AUTOSAR XML (schema 4-3-0)
package /Comp_FDC_ARPkg
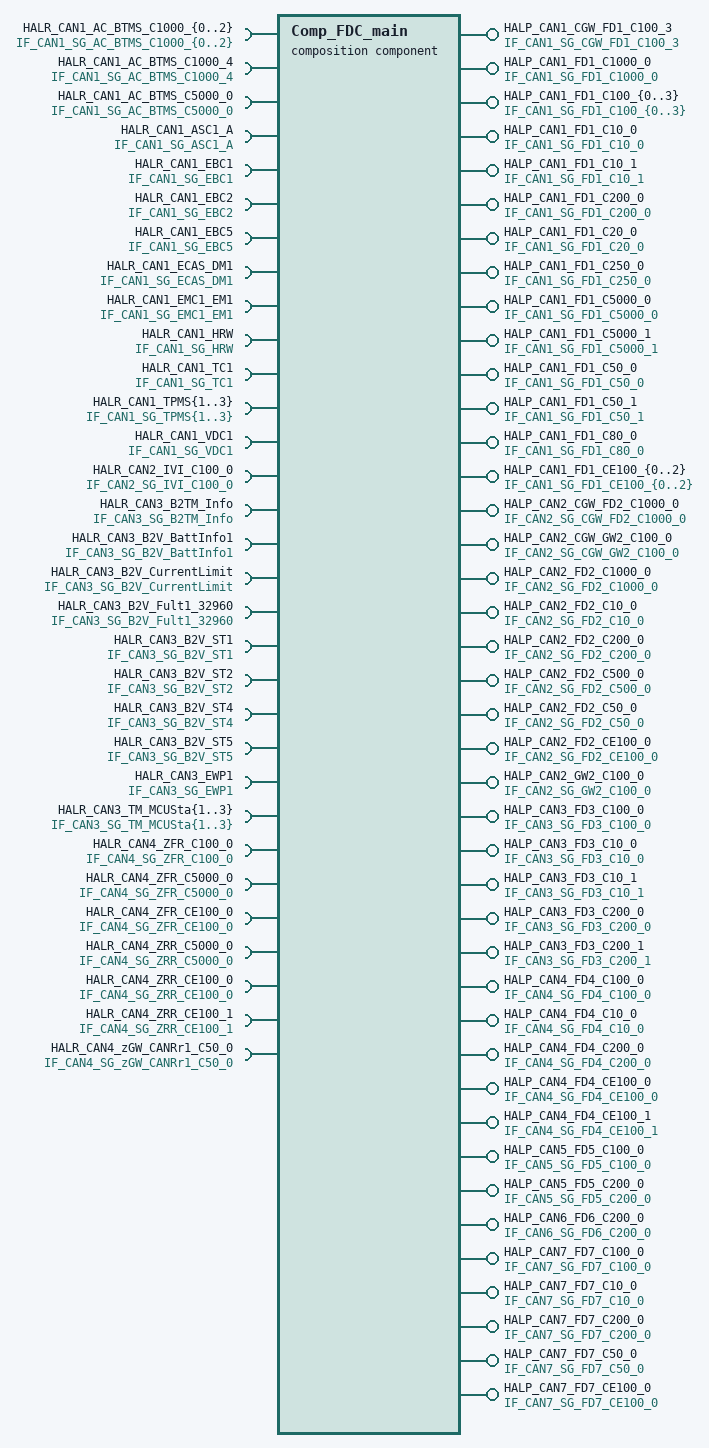
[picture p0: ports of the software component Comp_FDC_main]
  composition sw component type Comp_FDC_main
    46 x provide port:
      HALP_CAN1_CGW_FD1_C100_3: nonqueued-sender-com-spec{data-element=CAN1_SG_CGW_FD1_C100_3, handle-out-of-range=DEFAULT, init-value=constant-reference=Init_CAN1_SG_CGW_FD1_C100_3}, provided-interface=IF_CAN1_SG_CGW_FD1_C100_3
      HALP_CAN1_FD1_C1000_0: nonqueued-sender-com-spec{data-element=CAN1_SG_FD1_C1000_0, handle-out-of-range=DEFAULT, init-value=constant-reference=Init_CAN1_SG_FD1_C1000_0}, provided-interface=IF_CAN1_SG_FD1_C1000_0
      HALP_CAN1_FD1_C100_{0..3}: nonqueued-sender-com-spec{data-element=CAN1_SG_FD1_C100_{0..3}, handle-out-of-range=DEFAULT, init-value=constant-reference=Init_CAN1_SG_FD1_C100_{0..3}}, provided-interface=IF_CAN1_SG_FD1_C100_{0..3}
      HALP_CAN1_FD1_C10_0: nonqueued-sender-com-spec{data-element=CAN1_SG_FD1_C10_0, handle-out-of-range=DEFAULT, init-value=constant-reference=Init_CAN1_SG_FD1_C10_0}, provided-interface=IF_CAN1_SG_FD1_C10_0
      HALP_CAN1_FD1_C10_1: nonqueued-sender-com-spec{data-element=CAN1_SG_FD1_C10_1, handle-out-of-range=DEFAULT, init-value=constant-reference=Init_CAN1_SG_FD1_C10_1}, provided-interface=IF_CAN1_SG_FD1_C10_1
      HALP_CAN1_FD1_C200_0: nonqueued-sender-com-spec{data-element=CAN1_SG_FD1_C200_0, handle-out-of-range=DEFAULT, init-value=constant-reference=Init_CAN1_SG_FD1_C200_0}, provided-interface=IF_CAN1_SG_FD1_C200_0
      HALP_CAN1_FD1_C20_0: nonqueued-sender-com-spec{data-element=CAN1_SG_FD1_C20_0, handle-out-of-range=DEFAULT, init-value=constant-reference=Init_CAN1_SG_FD1_C20_0}, provided-interface=IF_CAN1_SG_FD1_C20_0
      HALP_CAN1_FD1_C250_0: nonqueued-sender-com-spec{data-element=CAN1_SG_FD1_C250_0, handle-out-of-range=DEFAULT, init-value=constant-reference=Init_CAN1_SG_FD1_C250_0}, provided-interface=IF_CAN1_SG_FD1_C250_0
      HALP_CAN1_FD1_C5000_0: nonqueued-sender-com-spec{data-element=CAN1_SG_FD1_C5000_0, handle-out-of-range=DEFAULT, init-value=constant-reference=Init_CAN1_SG_FD1_C5000_0}, provided-interface=IF_CAN1_SG_FD1_C5000_0
      HALP_CAN1_FD1_C5000_1: nonqueued-sender-com-spec{data-element=CAN1_SG_FD1_C5000_1, handle-out-of-range=DEFAULT, init-value=constant-reference=Init_CAN1_SG_FD1_C5000_1}, provided-interface=IF_CAN1_SG_FD1_C5000_1
      HALP_CAN1_FD1_C50_0: nonqueued-sender-com-spec{data-element=CAN1_SG_FD1_C50_0, handle-out-of-range=DEFAULT, init-value=constant-reference=Init_CAN1_SG_FD1_C50_0}, provided-interface=IF_CAN1_SG_FD1_C50_0
      HALP_CAN1_FD1_C50_1: nonqueued-sender-com-spec{data-element=CAN1_SG_FD1_C50_1, handle-out-of-range=DEFAULT, init-value=constant-reference=Init_CAN1_SG_FD1_C50_1}, provided-interface=IF_CAN1_SG_FD1_C50_1
      HALP_CAN1_FD1_C80_0: nonqueued-sender-com-spec{data-element=CAN1_SG_FD1_C80_0, handle-out-of-range=DEFAULT, init-value=constant-reference=Init_CAN1_SG_FD1_C80_0}, provided-interface=IF_CAN1_SG_FD1_C80_0
      HALP_CAN1_FD1_CE100_{0..2}: nonqueued-sender-com-spec{data-element=CAN1_SG_FD1_CE100_{0..2}, handle-out-of-range=DEFAULT, init-value=constant-reference=Init_CAN1_SG_FD1_CE100_{0..2}}, provided-interface=IF_CAN1_SG_FD1_CE100_{0..2}
      HALP_CAN2_CGW_FD2_C1000_0: nonqueued-sender-com-spec{data-element=CAN2_SG_CGW_FD2_C1000_0, handle-out-of-range=DEFAULT, init-value=constant-reference=Init_CAN2_SG_CGW_FD2_C1000_0}, provided-interface=IF_CAN2_SG_CGW_FD2_C1000_0
      HALP_CAN2_CGW_GW2_C100_0: nonqueued-sender-com-spec{data-element=CAN2_SG_CGW_GW2_C100_0, handle-out-of-range=DEFAULT, init-value=constant-reference=Init_CAN2_SG_CGW_GW2_C100_0}, provided-interface=IF_CAN2_SG_CGW_GW2_C100_0
      HALP_CAN2_FD2_C1000_0: nonqueued-sender-com-spec{data-element=CAN2_SG_FD2_C1000_0, handle-out-of-range=DEFAULT, init-value=constant-reference=Init_CAN2_SG_FD2_C1000_0}, provided-interface=IF_CAN2_SG_FD2_C1000_0
      HALP_CAN2_FD2_C10_0: nonqueued-sender-com-spec{data-element=CAN2_SG_FD2_C10_0, handle-out-of-range=DEFAULT, init-value=constant-reference=Init_CAN2_SG_FD2_C10_0}, provided-interface=IF_CAN2_SG_FD2_C10_0
      HALP_CAN2_FD2_C200_0: nonqueued-sender-com-spec{data-element=CAN2_SG_FD2_C200_0, handle-out-of-range=DEFAULT, init-value=constant-reference=Init_CAN2_SG_FD2_C200_0}, provided-interface=IF_CAN2_SG_FD2_C200_0
      HALP_CAN2_FD2_C500_0: nonqueued-sender-com-spec{data-element=CAN2_SG_FD2_C500_0, handle-out-of-range=DEFAULT, init-value=constant-reference=Init_CAN2_SG_FD2_C500_0}, provided-interface=IF_CAN2_SG_FD2_C500_0
      HALP_CAN2_FD2_C50_0: nonqueued-sender-com-spec{data-element=CAN2_SG_FD2_C50_0, handle-out-of-range=DEFAULT, init-value=constant-reference=Init_CAN2_SG_FD2_C50_0}, provided-interface=IF_CAN2_SG_FD2_C50_0
      HALP_CAN2_FD2_CE100_0: nonqueued-sender-com-spec{data-element=CAN2_SG_FD2_CE100_0, handle-out-of-range=DEFAULT, init-value=constant-reference=Init_CAN2_SG_FD2_CE100_0}, provided-interface=IF_CAN2_SG_FD2_CE100_0
      HALP_CAN2_GW2_C100_0: nonqueued-sender-com-spec{data-element=CAN2_SG_GW2_C100_0, handle-out-of-range=DEFAULT, init-value=constant-reference=Init_CAN2_SG_GW2_C100_0}, provided-interface=IF_CAN2_SG_GW2_C100_0
      HALP_CAN3_FD3_C100_0: nonqueued-sender-com-spec{data-element=CAN3_SG_FD3_C100_0, handle-out-of-range=DEFAULT, init-value=constant-reference=Init_CAN3_SG_FD3_C100_0}, provided-interface=IF_CAN3_SG_FD3_C100_0
      HALP_CAN3_FD3_C10_0: nonqueued-sender-com-spec{data-element=CAN3_SG_FD3_C10_0, handle-out-of-range=DEFAULT, init-value=constant-reference=Init_CAN3_SG_FD3_C10_0}, provided-interface=IF_CAN3_SG_FD3_C10_0
      HALP_CAN3_FD3_C10_1: nonqueued-sender-com-spec{data-element=CAN3_SG_FD3_C10_1, handle-out-of-range=DEFAULT, init-value=constant-reference=Init_CAN3_SG_FD3_C10_1}, provided-interface=IF_CAN3_SG_FD3_C10_1
      HALP_CAN3_FD3_C200_0: nonqueued-sender-com-spec{data-element=CAN3_SG_FD3_C200_0, handle-out-of-range=DEFAULT, init-value=constant-reference=Init_CAN3_SG_FD3_C200_0}, provided-interface=IF_CAN3_SG_FD3_C200_0
      HALP_CAN3_FD3_C200_1: nonqueued-sender-com-spec{data-element=CAN3_SG_FD3_C200_1, handle-out-of-range=DEFAULT, init-value=constant-reference=Init_CAN3_SG_FD3_C200_1}, provided-interface=IF_CAN3_SG_FD3_C200_1
      HALP_CAN4_FD4_C100_0: nonqueued-sender-com-spec{data-element=CAN4_SG_FD4_C100_0, handle-out-of-range=DEFAULT, init-value=constant-reference=Init_CAN4_SG_FD4_C100_0}, provided-interface=IF_CAN4_SG_FD4_C100_0
      HALP_CAN4_FD4_C10_0: nonqueued-sender-com-spec{data-element=CAN4_SG_FD4_C10_0, handle-out-of-range=DEFAULT, init-value=constant-reference=Init_CAN4_SG_FD4_C10_0}, provided-interface=IF_CAN4_SG_FD4_C10_0
      HALP_CAN4_FD4_C200_0: nonqueued-sender-com-spec{data-element=CAN4_SG_FD4_C200_0, handle-out-of-range=DEFAULT, init-value=constant-reference=Init_CAN4_SG_FD4_C200_0}, provided-interface=IF_CAN4_SG_FD4_C200_0
      HALP_CAN4_FD4_CE100_0: nonqueued-sender-com-spec{data-element=CAN4_SG_FD4_CE100_0, handle-out-of-range=DEFAULT, init-value=constant-reference=Init_CAN4_SG_FD4_CE100_0}, provided-interface=IF_CAN4_SG_FD4_CE100_0
      HALP_CAN4_FD4_CE100_1: nonqueued-sender-com-spec{data-element=CAN4_SG_FD4_CE100_1, handle-out-of-range=DEFAULT, init-value=constant-reference=Init_CAN4_SG_FD4_CE100_1}, provided-interface=IF_CAN4_SG_FD4_CE100_1
      HALP_CAN5_FD5_C100_0: nonqueued-sender-com-spec{data-element=CAN5_SG_FD5_C100_0, handle-out-of-range=DEFAULT, init-value=constant-reference=Init_CAN5_SG_FD5_C100_0}, provided-interface=IF_CAN5_SG_FD5_C100_0
      HALP_CAN5_FD5_C200_0: nonqueued-sender-com-spec{data-element=CAN5_SG_FD5_C200_0, handle-out-of-range=DEFAULT, init-value=constant-reference=Init_CAN5_SG_FD5_C200_0}, provided-interface=IF_CAN5_SG_FD5_C200_0
      HALP_CAN6_FD6_C200_0: nonqueued-sender-com-spec{data-element=CAN6_SG_FD6_C200_0, handle-out-of-range=DEFAULT, init-value=constant-reference=Init_CAN6_SG_FD6_C200_0}, provided-interface=IF_CAN6_SG_FD6_C200_0
      HALP_CAN7_FD7_C100_0: nonqueued-sender-com-spec{data-element=CAN7_SG_FD7_C100_0, handle-out-of-range=DEFAULT, init-value=constant-reference=Init_CAN7_SG_FD7_C100_0}, provided-interface=IF_CAN7_SG_FD7_C100_0
      HALP_CAN7_FD7_C10_0: nonqueued-sender-com-spec{data-element=CAN7_SG_FD7_C10_0, handle-out-of-range=DEFAULT, init-value=constant-reference=Init_CAN7_SG_FD7_C10_0}, provided-interface=IF_CAN7_SG_FD7_C10_0
      HALP_CAN7_FD7_C200_0: nonqueued-sender-com-spec{data-element=CAN7_SG_FD7_C200_0, handle-out-of-range=DEFAULT, init-value=constant-reference=Init_CAN7_SG_FD7_C200_0}, provided-interface=IF_CAN7_SG_FD7_C200_0
      HALP_CAN7_FD7_C50_0: nonqueued-sender-com-spec{data-element=CAN7_SG_FD7_C50_0, handle-out-of-range=DEFAULT, init-value=constant-reference=Init_CAN7_SG_FD7_C50_0}, provided-interface=IF_CAN7_SG_FD7_C50_0
      HALP_CAN7_FD7_CE100_0: nonqueued-sender-com-spec{data-element=CAN7_SG_FD7_CE100_0, handle-out-of-range=DEFAULT, init-value=constant-reference=Init_CAN7_SG_FD7_CE100_0}, provided-interface=IF_CAN7_SG_FD7_CE100_0
    37 x require port:
      HALR_CAN1_AC_BTMS_C1000_{0..2}: nonqueued-receiver-com-spec{data-element=CAN1_SG_AC_BTMS_C1000_{0..2}, handle-out-of-range=DEFAULT, enable-update=true, init-value=constant-reference=Init_CAN1_SG_AC_BTMS_C1000_{0..2}}, required-interface=IF_CAN1_SG_AC_BTMS_C1000_{0..2}
      HALR_CAN1_AC_BTMS_C1000_4: nonqueued-receiver-com-spec{data-element=CAN1_SG_AC_BTMS_C1000_4, handle-out-of-range=DEFAULT, enable-update=true, init-value=constant-reference=Init_CAN1_SG_AC_BTMS_C1000_4}, required-interface=IF_CAN1_SG_AC_BTMS_C1000_4
      HALR_CAN1_AC_BTMS_C5000_0: nonqueued-receiver-com-spec{data-element=CAN1_SG_AC_BTMS_C5000_0, handle-out-of-range=DEFAULT, enable-update=true, init-value=constant-reference=Init_CAN1_SG_AC_BTMS_C5000_0}, required-interface=IF_CAN1_SG_AC_BTMS_C5000_0
      HALR_CAN1_ASC1_A: nonqueued-receiver-com-spec{data-element=CAN1_SG_ASC1_A, handle-out-of-range=DEFAULT, enable-update=true, init-value=constant-reference=Init_CAN1_SG_ASC1_A}, required-interface=IF_CAN1_SG_ASC1_A
      HALR_CAN1_EBC1: nonqueued-receiver-com-spec{data-element=CAN1_SG_EBC1, handle-out-of-range=DEFAULT, enable-update=true, init-value=constant-reference=Init_CAN1_SG_EBC1}, required-interface=IF_CAN1_SG_EBC1
      HALR_CAN1_EBC2: nonqueued-receiver-com-spec{data-element=CAN1_SG_EBC2, handle-out-of-range=DEFAULT, enable-update=true, init-value=constant-reference=Init_CAN1_SG_EBC2}, required-interface=IF_CAN1_SG_EBC2
      HALR_CAN1_EBC5: nonqueued-receiver-com-spec{data-element=CAN1_SG_EBC5, handle-out-of-range=DEFAULT, enable-update=true, init-value=constant-reference=Init_CAN1_SG_EBC5}, required-interface=IF_CAN1_SG_EBC5
      HALR_CAN1_ECAS_DM1: nonqueued-receiver-com-spec{data-element=CAN1_SG_ECAS_DM1, handle-out-of-range=DEFAULT, enable-update=true, init-value=constant-reference=Init_CAN1_SG_ECAS_DM1}, required-interface=IF_CAN1_SG_ECAS_DM1
      HALR_CAN1_EMC1_EM1: nonqueued-receiver-com-spec{data-element=CAN1_SG_EMC1_EM1, handle-out-of-range=DEFAULT, enable-update=true, init-value=constant-reference=Init_CAN1_SG_EMC1_EM1}, required-interface=IF_CAN1_SG_EMC1_EM1
      HALR_CAN1_HRW: nonqueued-receiver-com-spec{data-element=CAN1_SG_HRW, handle-out-of-range=DEFAULT, enable-update=true, init-value=constant-reference=Init_CAN1_SG_HRW}, required-interface=IF_CAN1_SG_HRW
      HALR_CAN1_TC1: nonqueued-receiver-com-spec{data-element=CAN1_SG_TC1, handle-out-of-range=DEFAULT, enable-update=true, init-value=constant-reference=Init_CAN1_SG_TC1}, required-interface=IF_CAN1_SG_TC1
      HALR_CAN1_TPMS{1..3}: nonqueued-receiver-com-spec{data-element=CAN1_SG_TPMS{1..3}, handle-out-of-range=DEFAULT, enable-update=true, init-value=constant-reference=Init_CAN1_SG_TPMS{1..3}}, required-interface=IF_CAN1_SG_TPMS{1..3}
      HALR_CAN1_VDC1: nonqueued-receiver-com-spec{data-element=CAN1_SG_VDC1, handle-out-of-range=DEFAULT, enable-update=true, init-value=constant-reference=Init_CAN1_SG_VDC1}, required-interface=IF_CAN1_SG_VDC1
      HALR_CAN2_IVI_C100_0: nonqueued-receiver-com-spec{data-element=CAN2_SG_IVI_C100_0, handle-out-of-range=DEFAULT, enable-update=true, init-value=constant-reference=Init_CAN2_SG_IVI_C100_0}, required-interface=IF_CAN2_SG_IVI_C100_0
      HALR_CAN3_B2TM_Info: nonqueued-receiver-com-spec{data-element=CAN3_SG_B2TM_Info, handle-out-of-range=DEFAULT, enable-update=true, init-value=constant-reference=Init_CAN3_SG_B2TM_Info}, required-interface=IF_CAN3_SG_B2TM_Info
      HALR_CAN3_B2V_BattInfo1: nonqueued-receiver-com-spec{data-element=CAN3_SG_B2V_BattInfo1, handle-out-of-range=DEFAULT, enable-update=true, init-value=constant-reference=Init_CAN3_SG_B2V_BattInfo1}, required-interface=IF_CAN3_SG_B2V_BattInfo1
      HALR_CAN3_B2V_CurrentLimit: nonqueued-receiver-com-spec{data-element=CAN3_SG_B2V_CurrentLimit, handle-out-of-range=DEFAULT, enable-update=true, init-value=constant-reference=Init_CAN3_SG_B2V_CurrentLimit}, required-interface=IF_CAN3_SG_B2V_CurrentLimit
      HALR_CAN3_B2V_Fult1_32960: nonqueued-receiver-com-spec{data-element=CAN3_SG_B2V_Fult1_32960, handle-out-of-range=DEFAULT, enable-update=true, init-value=constant-reference=Init_CAN3_SG_B2V_Fult1_32960}, required-interface=IF_CAN3_SG_B2V_Fult1_32960
      HALR_CAN3_B2V_ST1: nonqueued-receiver-com-spec{data-element=CAN3_SG_B2V_ST1, handle-out-of-range=DEFAULT, enable-update=true, init-value=constant-reference=Init_CAN3_SG_B2V_ST1}, required-interface=IF_CAN3_SG_B2V_ST1
      HALR_CAN3_B2V_ST2: nonqueued-receiver-com-spec{data-element=CAN3_SG_B2V_ST2, handle-out-of-range=DEFAULT, enable-update=true, init-value=constant-reference=Init_CAN3_SG_B2V_ST2}, required-interface=IF_CAN3_SG_B2V_ST2
      HALR_CAN3_B2V_ST4: nonqueued-receiver-com-spec{data-element=CAN3_SG_B2V_ST4, handle-out-of-range=DEFAULT, enable-update=true, init-value=constant-reference=Init_CAN3_SG_B2V_ST4}, required-interface=IF_CAN3_SG_B2V_ST4
      HALR_CAN3_B2V_ST5: nonqueued-receiver-com-spec{data-element=CAN3_SG_B2V_ST5, handle-out-of-range=DEFAULT, enable-update=true, init-value=constant-reference=Init_CAN3_SG_B2V_ST5}, required-interface=IF_CAN3_SG_B2V_ST5
      HALR_CAN3_EWP1: nonqueued-receiver-com-spec{data-element=CAN3_SG_EWP1, handle-out-of-range=DEFAULT, enable-update=true, init-value=constant-reference=Init_CAN3_SG_EWP1}, required-interface=IF_CAN3_SG_EWP1
      HALR_CAN3_TM_MCUSta{1..3}: nonqueued-receiver-com-spec{data-element=CAN3_SG_TM_MCUSta{1..3}, handle-out-of-range=DEFAULT, enable-update=true, init-value=constant-reference=Init_CAN3_SG_TM_MCUSta{1..3}}, required-interface=IF_CAN3_SG_TM_MCUSta{1..3}
      HALR_CAN4_ZFR_C100_0: nonqueued-receiver-com-spec{data-element=CAN4_SG_ZFR_C100_0, handle-out-of-range=DEFAULT, enable-update=true, init-value=constant-reference=Init_CAN4_SG_ZFR_C100_0}, required-interface=IF_CAN4_SG_ZFR_C100_0
      HALR_CAN4_ZFR_C5000_0: nonqueued-receiver-com-spec{data-element=CAN4_SG_ZFR_C5000_0, handle-out-of-range=DEFAULT, enable-update=true, init-value=constant-reference=Init_CAN4_SG_ZFR_C5000_0}, required-interface=IF_CAN4_SG_ZFR_C5000_0
      HALR_CAN4_ZFR_CE100_0: nonqueued-receiver-com-spec{data-element=CAN4_SG_ZFR_CE100_0, handle-out-of-range=DEFAULT, enable-update=true, init-value=constant-reference=Init_CAN4_SG_ZFR_CE100_0}, required-interface=IF_CAN4_SG_ZFR_CE100_0
      HALR_CAN4_ZRR_C5000_0: nonqueued-receiver-com-spec{data-element=CAN4_SG_ZRR_C5000_0, handle-out-of-range=DEFAULT, enable-update=true, init-value=constant-reference=Init_CAN4_SG_ZRR_C5000_0}, required-interface=IF_CAN4_SG_ZRR_C5000_0
      HALR_CAN4_ZRR_CE100_0: nonqueued-receiver-com-spec{data-element=CAN4_SG_ZRR_CE100_0, handle-out-of-range=DEFAULT, enable-update=true, init-value=constant-reference=Init_CAN4_SG_ZRR_CE100_0}, required-interface=IF_CAN4_SG_ZRR_CE100_0
      HALR_CAN4_ZRR_CE100_1: nonqueued-receiver-com-spec{data-element=CAN4_SG_ZRR_CE100_1, handle-out-of-range=DEFAULT, enable-update=true, init-value=constant-reference=Init_CAN4_SG_ZRR_CE100_1}, required-interface=IF_CAN4_SG_ZRR_CE100_1
      HALR_CAN4_zGW_CANRr1_C50_0: nonqueued-receiver-com-spec{data-element=CAN4_SG_zGW_CANRr1_C50_0, handle-out-of-range=DEFAULT, enable-update=true, init-value=constant-reference=Init_CAN4_SG_zGW_CANRr1_C50_0}, required-interface=IF_CAN4_SG_zGW_CANRr1_C50_0
    20 x component:
      BswMTest: type=BswMTest_type
      SWC_APS: type=SWC_APS_type
      SWC_CDD: type=SWC_CDD_type
      SWC_CGW: type=SWC_CGW_type
      SWC_DID: type=SWC_DID_type
      SWC_DKC: type=SWC_DKC_type
      SWC_FDC: type=SWC_FDC_type
      SWC_HALIN: type=SWC_HALIN_type
      SWC_HALIN_CDD: type=SWC_HALIN_CDD_type
      SWC_IMU: type=SWC_IMU_type
      SWC_INP: type=SWC_INP_type
      SWC_IOEXP: type=SWC_IOEXP_type
      SWC_OUTP: type=SWC_OUTP_type
      SWC_HALOUT: type=SWC_HALOUT_type
      SWC_LOG: type=SWC_LOG_type
      SWC_NVM: type=SWC_NVM_type
      SWC_SCP: type=SWC_SCP_type
      SWC_UART: type=SWC_UART_type
      SWC_UDS: type=SWC_UDS_type
      SWC_VES: type=SWC_VES_type
    delegate SWC_HALIN.R_CAN1_AC_BTMS_C1000_0 <-> outer port HALR_CAN1_AC_BTMS_C1000_0
    delegate SWC_HALIN.R_CAN1_AC_BTMS_C1000_1 <-> outer port HALR_CAN1_AC_BTMS_C1000_1
    delegate SWC_HALIN.R_CAN1_AC_BTMS_C1000_4 <-> outer port HALR_CAN1_AC_BTMS_C1000_4
    delegate SWC_HALIN.R_CAN1_AC_BTMS_C5000_0 <-> outer port HALR_CAN1_AC_BTMS_C5000_0
    delegate SWC_HALIN.R_CAN1_ASC1_A <-> outer port HALR_CAN1_ASC1_A
    delegate SWC_HALIN.R_CAN1_EBC1 <-> outer port HALR_CAN1_EBC1
    delegate SWC_HALIN.R_CAN1_EBC2 <-> outer port HALR_CAN1_EBC2
    delegate SWC_HALIN.R_CAN1_EBC5 <-> outer port HALR_CAN1_EBC5
    delegate SWC_HALIN.R_CAN1_ECAS_DM1 <-> outer port HALR_CAN1_ECAS_DM1
    delegate SWC_HALIN.R_CAN1_EMC1_EM1 <-> outer port HALR_CAN1_EMC1_EM1
    delegate SWC_HALIN.R_CAN1_HRW <-> outer port HALR_CAN1_HRW
    delegate SWC_HALIN.R_CAN1_TC1 <-> outer port HALR_CAN1_TC1
    delegate SWC_HALIN.R_CAN2_IVI_C100_0 <-> outer port HALR_CAN2_IVI_C100_0
    delegate SWC_HALIN.R_CAN3_B2TM_Info <-> outer port HALR_CAN3_B2TM_Info
    delegate SWC_HALIN.R_CAN3_B2V_BattInfo1 <-> outer port HALR_CAN3_B2V_BattInfo1
    delegate SWC_HALIN.R_CAN3_B2V_CurrentLimit <-> outer port HALR_CAN3_B2V_CurrentLimit
    delegate SWC_HALIN.R_CAN3_B2V_Fult1_32960 <-> outer port HALR_CAN3_B2V_Fult1_32960
    delegate SWC_HALIN.R_CAN3_B2V_ST1 <-> outer port HALR_CAN3_B2V_ST1
    delegate SWC_HALIN.R_CAN3_B2V_ST2 <-> outer port HALR_CAN3_B2V_ST2
    delegate SWC_HALIN.R_CAN3_B2V_ST4 <-> outer port HALR_CAN3_B2V_ST4
    delegate SWC_HALIN.R_CAN3_B2V_ST5 <-> outer port HALR_CAN3_B2V_ST5
    delegate SWC_HALIN.R_CAN3_EWP1 <-> outer port HALR_CAN3_EWP1
    delegate SWC_HALIN.R_CAN3_TM_MCUSta{1..3} <-> outer port HALR_CAN3_TM_MCUSta{1..3}
    delegate SWC_HALIN.R_CAN4_ZFR_C100_0 <-> outer port HALR_CAN4_ZFR_C100_0
    delegate SWC_HALIN.R_CAN4_ZFR_CE100_0 <-> outer port HALR_CAN4_ZFR_CE100_0
    delegate SWC_HALIN.R_CAN4_ZRR_CE100_0 <-> outer port HALR_CAN4_ZRR_CE100_0
    delegate SWC_HALIN.R_CAN4_ZRR_CE100_1 <-> outer port HALR_CAN4_ZRR_CE100_1
    delegate SWC_HALIN.R_CAN4_zGW_CANRr1_C50_0 <-> outer port HALR_CAN4_zGW_CANRr1_C50_0
    delegate SWC_CGW.R_CAN1_AC_BTMS_C1000_1 <-> outer port HALR_CAN1_AC_BTMS_C1000_1
    delegate SWC_CGW.R_CAN1_AC_BTMS_C1000_2 <-> outer port HALR_CAN1_AC_BTMS_C1000_2
    delegate SWC_CGW.R_CAN1_AC_BTMS_C5000_0 <-> outer port HALR_CAN1_AC_BTMS_C5000_0
    delegate SWC_CGW.R_CAN1_ASC1_A <-> outer port HALR_CAN1_ASC1_A
    delegate SWC_CGW.R_CAN1_EBC1 <-> outer port HALR_CAN1_EBC1
    delegate SWC_CGW.R_CAN1_ECAS_DM1 <-> outer port HALR_CAN1_ECAS_DM1
    delegate SWC_CGW.R_CAN1_HRW <-> outer port HALR_CAN1_HRW
    delegate SWC_CGW.R_CAN1_TC1 <-> outer port HALR_CAN1_TC1
    delegate SWC_CGW.R_CAN1_TPMS{1..3} <-> outer port HALR_CAN1_TPMS{1..3}
    delegate SWC_CGW.R_CAN1_VDC1 <-> outer port HALR_CAN1_VDC1
    delegate SWC_CGW.R_CAN3_B2TM_Info <-> outer port HALR_CAN3_B2TM_Info
    delegate SWC_CGW.R_CAN3_B2V_BattInfo1 <-> outer port HALR_CAN3_B2V_BattInfo1
    delegate SWC_CGW.R_CAN3_B2V_ST1 <-> outer port HALR_CAN3_B2V_ST1
    delegate SWC_CGW.R_CAN3_B2V_ST2 <-> outer port HALR_CAN3_B2V_ST2
    delegate SWC_CGW.R_CAN3_TM_MCUSta2 <-> outer port HALR_CAN3_TM_MCUSta2
    delegate SWC_CGW.R_CAN4_ZFR_C100_0 <-> outer port HALR_CAN4_ZFR_C100_0
    delegate SWC_CGW.R_CAN4_ZFR_C5000_0 <-> outer port HALR_CAN4_ZFR_C5000_0
    delegate SWC_CGW.R_CAN4_ZFR_CE100_0 <-> outer port HALR_CAN4_ZFR_CE100_0
    delegate SWC_CGW.R_CAN4_ZRR_C5000_0 <-> outer port HALR_CAN4_ZRR_C5000_0
    delegate SWC_CGW.R_CAN4_ZRR_CE100_1 <-> outer port HALR_CAN4_ZRR_CE100_1
    delegate SWC_CGW.R_CAN4_zGW_CANRr1_C50_0 <-> outer port HALR_CAN4_zGW_CANRr1_C50_0
    delegate SWC_HALOUT.P_CAN1_FD1_C100_{0..3} <-> outer port HALP_CAN1_FD1_C100_{0..3}
    delegate SWC_HALOUT.P_CAN1_FD1_C10_0 <-> outer port HALP_CAN1_FD1_C10_0
    delegate SWC_HALOUT.P_CAN1_FD1_C10_1 <-> outer port HALP_CAN1_FD1_C10_1
    delegate SWC_HALOUT.P_CAN1_FD1_C200_0 <-> outer port HALP_CAN1_FD1_C200_0
    delegate SWC_HALOUT.P_CAN1_FD1_C20_0 <-> outer port HALP_CAN1_FD1_C20_0
    delegate SWC_HALOUT.P_CAN1_FD1_C250_0 <-> outer port HALP_CAN1_FD1_C250_0
    delegate SWC_HALOUT.P_CAN1_FD1_C5000_0 <-> outer port HALP_CAN1_FD1_C5000_0
    delegate SWC_HALOUT.P_CAN1_FD1_C5000_1 <-> outer port HALP_CAN1_FD1_C5000_1
    delegate SWC_HALOUT.P_CAN1_FD1_C50_0 <-> outer port HALP_CAN1_FD1_C50_0
    delegate SWC_HALOUT.P_CAN1_FD1_C50_1 <-> outer port HALP_CAN1_FD1_C50_1
    delegate SWC_HALOUT.P_CAN1_FD1_C80_0 <-> outer port HALP_CAN1_FD1_C80_0
    delegate SWC_HALOUT.P_CAN1_FD1_CE100_{0..2} <-> outer port HALP_CAN1_FD1_CE100_{0..2}
    delegate SWC_HALOUT.P_CAN2_FD2_C1000_0 <-> outer port HALP_CAN2_FD2_C1000_0
    delegate SWC_HALOUT.P_CAN2_FD2_C10_0 <-> outer port HALP_CAN2_FD2_C10_0
    delegate SWC_HALOUT.P_CAN2_FD2_C200_0 <-> outer port HALP_CAN2_FD2_C200_0
    delegate SWC_HALOUT.P_CAN2_FD2_C500_0 <-> outer port HALP_CAN2_FD2_C500_0
    delegate SWC_HALOUT.P_CAN2_FD2_C50_0 <-> outer port HALP_CAN2_FD2_C50_0
    delegate SWC_HALOUT.P_CAN2_FD2_CE100_0 <-> outer port HALP_CAN2_FD2_CE100_0
    delegate SWC_HALOUT.P_CAN2_GW2_C100_0 <-> outer port HALP_CAN2_GW2_C100_0
    delegate SWC_HALOUT.P_CAN3_FD3_C100_0 <-> outer port HALP_CAN3_FD3_C100_0
    delegate SWC_HALOUT.P_CAN3_FD3_C10_0 <-> outer port HALP_CAN3_FD3_C10_0
    delegate SWC_HALOUT.P_CAN3_FD3_C10_1 <-> outer port HALP_CAN3_FD3_C10_1
    delegate SWC_HALOUT.P_CAN3_FD3_C200_0 <-> outer port HALP_CAN3_FD3_C200_0
    delegate SWC_HALOUT.P_CAN3_FD3_C200_1 <-> outer port HALP_CAN3_FD3_C200_1
    delegate SWC_HALOUT.P_CAN4_FD4_C100_0 <-> outer port HALP_CAN4_FD4_C100_0
    delegate SWC_HALOUT.P_CAN4_FD4_C10_0 <-> outer port HALP_CAN4_FD4_C10_0
    delegate SWC_HALOUT.P_CAN4_FD4_C200_0 <-> outer port HALP_CAN4_FD4_C200_0
    delegate SWC_HALOUT.P_CAN4_FD4_CE100_0 <-> outer port HALP_CAN4_FD4_CE100_0
    delegate SWC_HALOUT.P_CAN4_FD4_CE100_1 <-> outer port HALP_CAN4_FD4_CE100_1
    delegate SWC_HALOUT.P_CAN5_FD5_C100_0 <-> outer port HALP_CAN5_FD5_C100_0
    delegate SWC_HALOUT.P_CAN5_FD5_C200_0 <-> outer port HALP_CAN5_FD5_C200_0
    delegate SWC_HALOUT.P_CAN6_FD6_C200_0 <-> outer port HALP_CAN6_FD6_C200_0
    delegate SWC_HALOUT.P_CAN7_FD7_C100_0 <-> outer port HALP_CAN7_FD7_C100_0
    delegate SWC_HALOUT.P_CAN7_FD7_C10_0 <-> outer port HALP_CAN7_FD7_C10_0
    delegate SWC_HALOUT.P_CAN7_FD7_C200_0 <-> outer port HALP_CAN7_FD7_C200_0
    delegate SWC_HALOUT.P_CAN7_FD7_C50_0 <-> outer port HALP_CAN7_FD7_C50_0
    delegate SWC_HALOUT.P_CAN7_FD7_CE100_0 <-> outer port HALP_CAN7_FD7_CE100_0
    delegate SWC_CGW.P_CAN1_FD1_C1000_0 <-> outer port HALP_CAN1_FD1_C1000_0
    delegate SWC_CGW.P_CAN1_CGW_FD1_C100_3 <-> outer port HALP_CAN1_CGW_FD1_C100_3
    delegate SWC_CGW.P_CAN2_CGW_FD2_C1000_0 <-> outer port HALP_CAN2_CGW_FD2_C1000_0
    delegate SWC_CGW.P_CAN2_CGW_GW2_C100_0 <-> outer port HALP_CAN2_CGW_GW2_C100_0
    connect SWC_APS.P_HALINCDD_APS -> SWC_HALIN_CDD.R_HALIN_APS
    connect SWC_CDD.P_HALINCDD -> SWC_HALIN_CDD.R_HALINCDD
    connect SWC_UDS.P_UDSCDD -> SWC_HALIN_CDD.R_UDSCDD
    connect SWC_APS.P_HALOUTCDD_APS -> SWC_HALOUT.R_HALOUT_APS
    connect SWC_CDD.P_HALINCDD -> SWC_HALOUT.R_HALINCDD
    connect SWC_CDD.P_HALINCDD -> SWC_VES.R_HALINCDD
    connect SWC_CDD.P_HALOUTCDD -> SWC_HALOUT.R_HALOUTCDD
    connect SWC_DID.P_DIDReadCDD -> SWC_HALIN_CDD.R_DIDReadCDD
    connect SWC_DID.P_DIDWriteCDD -> SWC_HALOUT.R_DIDWriteCDD
    connect SWC_DKC.P_DKCCDD -> SWC_DKC.R_DKCCDD
    connect SWC_DKC.P_DKCData -> SWC_HALIN_CDD.R_DKCData
    connect SWC_HALOUT.P_AppModeReq -> BswMTest.R_AppModeReq
    connect SWC_HALOUT.P_FDCCDD_Inner -> SWC_HALOUT.R_FDCCDD_Inner
    connect SWC_HALIN_CDD.P_NVMReadCDD_Inner -> SWC_HALIN_CDD.R_NVMReadCDD_Inner
    connect SWC_HALOUT.P_NVMWriteCDD_Inner -> SWC_HALOUT.R_NVMWriteCDD_Inner
    connect SWC_HALOUT.P_NVMWrite -> SWC_NVM.R_WriteNVData
    connect SWC_HALIN.P_WDGCDD -> SWC_HALIN.R_WDGCDD
    connect SWC_HALOUT.P_WDGCDD -> SWC_HALOUT.R_WDGCDD
    connect SWC_HALIN.P_BHAL_CAN2_outputs -> SWC_HALIN_CDD.R_BHAL_CAN2_outputs
    connect SWC_HALIN.P_BHAL_CAN4_outputs -> SWC_HALIN_CDD.R_BHAL_CAN4_outputs
    connect SWC_HALIN.P_BHAL_CAN{1..4}_outputs -> SWC_INP.R_BHAL_CAN{1..4}_outputs
    connect SWC_HALIN_CDD.P_BHAL_APM_outputs -> SWC_INP.R_BHAL_APM_outputs
    connect SWC_HALIN_CDD.P_BHAL_DDM_outputs -> SWC_INP.R_BHAL_DDM_outputs
    connect SWC_HALIN_CDD.P_BHAL_DKC_outputs -> SWC_INP.R_BHAL_DKC_outputs
    connect SWC_HALIN_CDD.P_BHAL_GPIO_outputs -> SWC_INP.R_BHAL_GPIO_outputs
    connect SWC_HALIN_CDD.P_BHAL_IMU_outputs -> SWC_INP.R_BHAL_IMU_outputs
    connect SWC_HALIN_CDD.P_BHAL_SYS_outputs -> SWC_INP.R_BHAL_SYS_outputs
    connect SWC_HALIN_CDD.P_BHAL_SYS_outputs -> SWC_HALOUT.R_BHAL_SYS_outputs
    connect SWC_HALIN_CDD.P_BHAL_TPMS_outputs -> SWC_INP.R_BHAL_TPMS_outputs
    connect SWC_IMU.P_HAINICDD_IMU -> SWC_HALIN_CDD.R_HALIN_IMU
    connect SWC_INP.P_BINP_CAN1_outputs -> SWC_FDC.R_BINP_CAN1_outputs
    connect SWC_INP.P_BINP_CAN1_outputs -> SWC_SCP.R_BINP_CAN1_outputs
    connect SWC_INP.P_BINP_CAN2_outputs -> SWC_FDC.R_BINP_CAN2_outputs
    connect SWC_INP.P_BINP_CAN2_outputs -> SWC_SCP.R_BINP_CAN2_outputs
    connect SWC_INP.P_BINP_CAN3_outputs -> SWC_FDC.R_BINP_CAN3_outputs
    connect SWC_INP.P_BINP_CAN3_outputs -> SWC_SCP.R_BINP_CAN3_outputs
    connect SWC_INP.P_BINP_CAN4_outputs -> SWC_FDC.R_BINP_CAN4_outputs
    connect SWC_INP.P_BINP_CAN4_outputs -> SWC_SCP.R_BINP_CAN4_outputs
    connect SWC_INP.P_BINP_APM_outputs -> SWC_FDC.R_BINP_APM_outputs
    connect SWC_INP.P_BINP_DDM_outputs -> SWC_FDC.R_BINP_DDM_outputs
    connect SWC_INP.P_BINP_DKC_outputs -> SWC_FDC.R_BINP_DKC_outputs
    connect SWC_INP.P_BINP_GPIO_outputs -> SWC_FDC.R_BINP_GPIO_outputs
    connect SWC_INP.P_BINP_IMU_outputs -> SWC_FDC.R_BINP_IMU_outputs
    connect SWC_INP.P_BINP_SYS_outputs -> SWC_FDC.R_BINP_SYS_outputs
    connect SWC_INP.P_BINP_TPMS_outputs -> SWC_FDC.R_BINP_TPMS_outputs
    connect SWC_FDC.P_BACC_outputs -> SWC_OUTP.R_BACC_outputs
    connect SWC_FDC.P_BAPM_outputs -> SWC_OUTP.R_BAPM_outputs
    connect SWC_FDC.P_BBCM_outputs -> SWC_OUTP.R_BBCM_outputs
    connect SWC_FDC.P_BDDM_outputs -> SWC_OUTP.R_BDDM_outputs
    connect SWC_FDC.P_BDHP_outputs -> SWC_OUTP.R_BDHP_outputs
    connect SWC_FDC.P_BDKC_outputs -> SWC_OUTP.R_BDKC_outputs
    connect SWC_FDC.P_BDSC_outputs -> SWC_OUTP.R_BDSC_outputs
    connect SWC_FDC.P_BNMM_outputs -> SWC_OUTP.R_BNMM_outputs
    connect SWC_FDC.P_BPMM_outputs -> SWC_OUTP.R_BPMM_outputs
    connect SWC_FDC.P_BPSA_outputs -> SWC_OUTP.R_BPSA_outputs
    connect SWC_FDC.P_BSCP_outputs -> SWC_OUTP.R_BSCP_outputs
    connect SWC_FDC.P_BSYS_outputs -> SWC_OUTP.R_BSYS_outputs
    connect SWC_FDC.P_BTHC_outputs -> SWC_OUTP.R_BTHC_outputs
    connect SWC_FDC.P_BTPM_outputs -> SWC_OUTP.R_BTPM_outputs
    connect SWC_FDC.P_BTQD_outputs -> SWC_OUTP.R_BTQD_outputs
    connect SWC_FDC.P_BTQR_outputs -> SWC_OUTP.R_BTQR_outputs
    connect SWC_FDC.P_BV2L_outputs -> SWC_OUTP.R_BV2L_outputs
    connect SWC_FDC.P_BVMC_outputs -> SWC_OUTP.R_BVMC_outputs
    connect SWC_FDC.P_BDID_outputs -> SWC_OUTP.R_BDID_outputs
    connect SWC_OUTP.P_BOUTP_outputs -> SWC_HALOUT.R_BOUTP_outputs
    connect SWC_HALIN_CDD.P_BHAL_DID_outputs -> SWC_HALOUT.R_BHAL_DID_outputs
    connect SWC_IOEXP.P_IOExpIN_CDD -> SWC_HALIN_CDD.R_IOExpIN_CDD
    connect SWC_IOEXP.P_IOExpOUT_CDD -> SWC_HALOUT.R_IOExpOUT_CDD
    connect SWC_NVM.P_ReadNVData -> SWC_HALIN_CDD.R_NVMRead
    connect SWC_HALIN_CDD.P_NVMReadCDD -> SWC_HALOUT.R_NVMReadCDD
    connect SWC_SCP.P_BSCP_outputs -> SWC_HALOUT.R_BSCP_outputs
    connect SWC_UART.P_UARTCDD -> SWC_UART.R_UARTCDD
    connect SWC_UDS.P_UDSCDD -> SWC_HALOUT.R_UDSCDD
    connect SWC_HALOUT.P_J1939_CAN1_FD1_CE100_1 -> SWC_HALOUT.R_J1939_CAN1_FD1_CE100_1
    connect SWC_HALOUT.P_J1939_CAN1_FD1_CE100_0 -> SWC_HALOUT.R_J1939_CAN1_FD1_CE100_0
    connect SWC_VES.P_VESCDD -> SWC_VES.R_VESCDD
